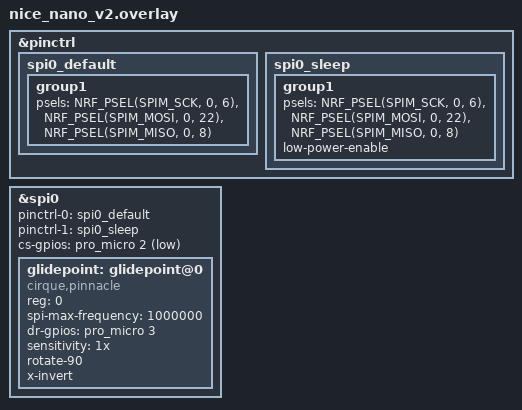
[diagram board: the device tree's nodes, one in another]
&pinctrl {
    /* configuration for spi0 device, default state */
    spi0_default: spi0_default {
        /* node name is arbitrary */
        group1 {
            /* main role: configure P0.06 (D1) as SPI clock, P0.22 (D4) as SPI MOSI, P0.08 (D0) as SPI MISO */
            psels = <NRF_PSEL(SPIM_SCK, 0, 6)>,
                    <NRF_PSEL(SPIM_MOSI, 0, 22)>,
                    <NRF_PSEL(SPIM_MISO, 0, 8)>;
        };
    };
    /* configuration for spi0 device, sleep state */
    spi0_sleep: spi0_sleep {
        group1 {
            /* main role: configure P0.06 (D1) as SPI clock, P0.22 (D4) as SPI MOSI, P0.08 (D0) as SPI MISO */
            psels = <NRF_PSEL(SPIM_SCK, 0, 6)>,
                    <NRF_PSEL(SPIM_MOSI, 0, 22)>,
                    <NRF_PSEL(SPIM_MISO, 0, 8)>;
            low-power-enable;
        };
    };
};
cirque_spi: &spi0 {
    status = "okay";
    pinctrl-0 = <&spi0_default>;
    pinctrl-1 = <&spi0_sleep>;
    pinctrl-names = "default", "sleep";

    cs-gpios = <&pro_micro 2 GPIO_ACTIVE_LOW>;
    glidepoint: glidepoint@0 {
        compatible = "cirque,pinnacle";
        reg = <0>;
        spi-max-frequency = <1000000>;
        status = "okay";
        dr-gpios = <&pro_micro 3 (GPIO_ACTIVE_HIGH)>;
        sensitivity = "1x";
        rotate-90;
        x-invert;
        // no-taps;
    };
};
